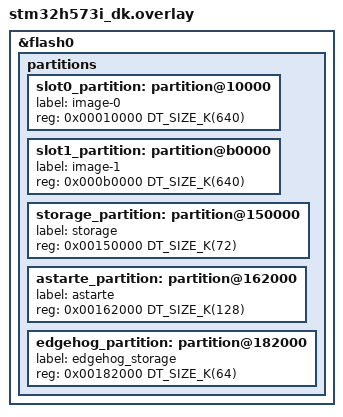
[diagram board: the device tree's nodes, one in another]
/*
 * (C) Copyright 2024, SECO Mind Srl
 *
 * SPDX-License-Identifier: Apache-2.0
 */

/delete-node/ &slot0_partition;
/delete-node/ &slot1_partition;
/delete-node/ &storage_partition;

&flash0 {
    partitions {
        slot0_partition: partition@10000 {
            label = "image-0";
            reg = <0x00010000 DT_SIZE_K(640)>;
        };

        slot1_partition: partition@b0000 {
            label = "image-1";
            reg = <0x000b0000 DT_SIZE_K(640)>;
        };

        storage_partition: partition@150000 {
            label = "storage";
            reg = <0x00150000 DT_SIZE_K(72)>;
        };

        astarte_partition: partition@162000 {
            label = "astarte";
            reg = <0x00162000 DT_SIZE_K(128)>;
        };

        edgehog_partition: partition@182000 {
            label = "edgehog_storage";
            reg = <0x00182000 DT_SIZE_K(64)>;
        };
    };
};
